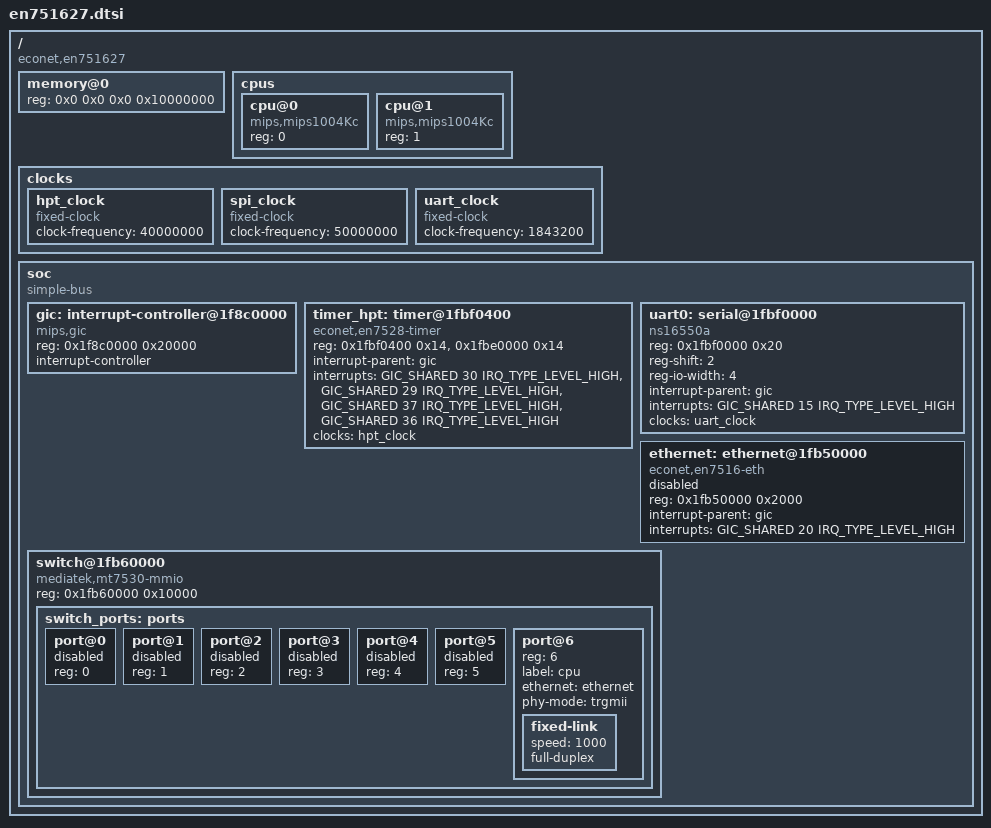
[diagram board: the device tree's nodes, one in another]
// SPDX-License-Identifier: GPL-2.0-only
/*
 * EcoNet EN751627 SoC core architecture infrastructure template layout
 * For OpenWrt Mainline PR compliance match alignment profiles.
 */

/ {
	compatible = "econet,en751627";
	#address-cells = <2>;
	#size-cells = <2>;

	/* Core System RAM: Handled directly by the early boot scanning engine */
	memory@0 {
		device_type = "memory";
		reg = <0x0 0x0 0x0 0x10000000>; /* Physical Base 0x0, Size 256MB */
	};

	/* Global Architecture CPU Array Matrix Allocation Space */
	cpus {
		#address-cells = <1>;
		#size-cells = <0>;

		cpu@0 {
			device_type = "cpu";
			compatible = "mips,mips1004Kc";
			reg = <0>;
		};

		cpu@1 {
			device_type = "cpu";
			compatible = "mips,mips1004Kc";
			reg = <1>;
		};
	};

	/* Fixed Base Clock Oscillators Matrix Infrastructure definitions */
	clocks {
		hpt_clock: hpt_clock {
			compatible = "fixed-clock";
			#clock-cells = <0>;
			clock-frequency = <40000000>; /* Fixed 40MHz Reference HPT clock */
		};

		spi_clock: spi_clock {
			compatible = "fixed-clock";
			#clock-cells = <0>;
			clock-frequency = <50000000>; /* Fixed 50MHz Reference SPI clock */
		};

		uart_clock: uart_clock {
			compatible = "fixed-clock";
			#clock-cells = <0>;
			clock-frequency = <1843200>; /* Standard 1.8432MHz UART base oscillator */
		};
	};

	/* 
	 * Unified System Bus Container Wrapper Block.
	 * Acts as an internal hardware bridge translating the global 64-bit 
	 * architecture scale down to flat, readable 32-bit peripheral layout space.
	 * This prevents any implicit address truncation faults during initialization loops.
	 */
	soc: soc {
		compatible = "simple-bus";
		#address-cells = <1>;
		#size-cells = <1>;
		/* Map the root's 64-bit space (0x0 0x0) down to clean 32-bit child register ranges */
		ranges = <0x0 0x0 0x0 0xffffffff>;

		/* Core Interrupt Controller Hardware Map Matrix Assignment */
		gic: interrupt-controller@1f8c0000 {
			compatible = "mips,gic";
			reg = <0x1f8c0000 0x20000>;
			interrupt-controller;
			#interrupt-cells = <3>;
		};

		/* High Performance Tracker System Clock Hardware Blocks Space */
		timer_hpt: timer@1fbf0400 { 
			compatible = "econet,en7528-timer";
			reg = <0x1fbf0400 0x14>,
			      <0x1fbe0000 0x14>;

			interrupt-parent = <&gic>;
			interrupts = <GIC_SHARED 30 IRQ_TYPE_LEVEL_HIGH>,
			             <GIC_SHARED 29 IRQ_TYPE_LEVEL_HIGH>,
			             <GIC_SHARED 37 IRQ_TYPE_LEVEL_HIGH>,
			             <GIC_SHARED 36 IRQ_TYPE_LEVEL_HIGH>;

			clocks = <&hpt_clock>;   
		};

		/* Memory-Mapped Native Hardware UART Line Diagnostics Controller */
		uart0: serial@1fbf0000 {
			compatible = "ns16550a";
			reg = <0x1fbf0000 0x20>;
			reg-shift = <2>;
			reg-io-width = <4>;
			interrupt-parent = <&gic>;
			interrupts = <GIC_SHARED 15 IRQ_TYPE_LEVEL_HIGH>;
			clocks = <&uart_clock>;
			status = "okay";
		};

		/* 
		 * Core Integrated Gigabit Frame Engine Media Link Subsystem.
		 * Explicitly labeled as 'ethernet' to answer the exact downstream 
		 * phandle reference checks compiled inside your Zyxel child dts nodes.
		 */
		ethernet: ethernet@1fb50000 {
			compatible = "econet,en7516-eth";
			reg = <0x1fb50000 0x2000>;
			interrupt-parent = <&gic>;
			interrupts = <GIC_SHARED 20 IRQ_TYPE_LEVEL_HIGH>;
			status = "disabled";
		};

		/* 
		 * Integrated Internal MT7530 Silicon Switch Engine Block Allocation.
		 * Safely nested inside the 32-bit Simple-Bus scope, avoiding register padding bloat.
		 */
		switch@1fb60000 {
			compatible = "mediatek,mt7530-mmio";
			reg = <0x1fb60000 0x10000>;
			status = "okay";

			switch_ports: ports {
				#address-cells = <1>;
				#size-cells = <0>;

				port@0 { reg = <0>; status = "disabled"; };
				port@1 { reg = <1>; status = "disabled"; };
				port@2 { reg = <2>; status = "disabled"; };
				port@3 { reg = <3>; status = "disabled"; };
				port@4 { reg = <4>; status = "disabled"; };
				port@5 { reg = <5>; status = "disabled"; };

				port@6 {
					reg = <6>;
					label = "cpu";
					ethernet = <&ethernet>;
					phy-mode = "trgmii";

					fixed-link {
						speed = <1000>;
						full-duplex;
					};
				};
			};
		};
	};
};
